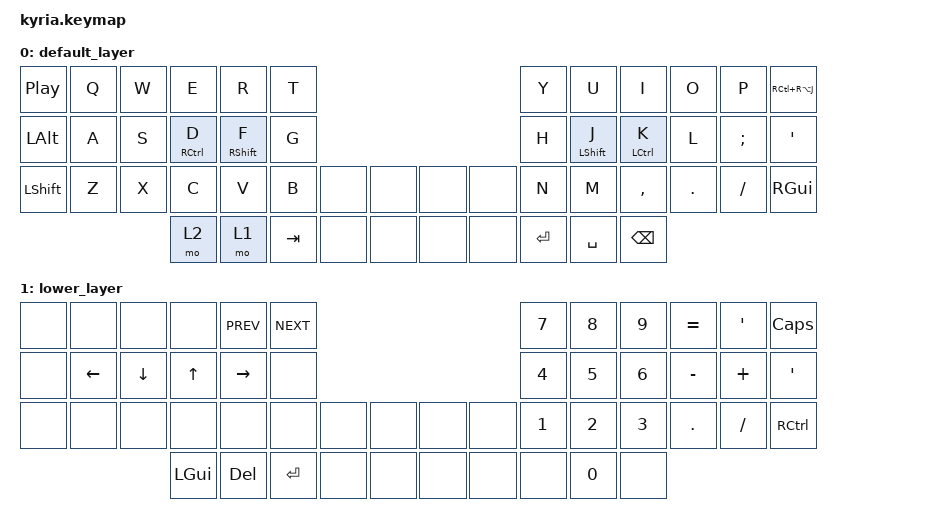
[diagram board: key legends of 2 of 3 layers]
/*
 * Copyright (c) 2020 The ZMK Contributors
 *
 * SPDX-License-Identifier: MIT
 */

#include <behaviors.dtsi>
#include <dt-bindings/zmk/keys.h>
#include <dt-bindings/zmk/bt.h>
&left_encoder { resolution = <3>; };
&kscan0 {
    debounce-period = <7>;
};

/ {
    combos {
        compatible = "zmk,combos";
        combo_esc {
            timeout-ms = <80>;
            key-positions = <5 17>;
            bindings = <&kp LALT>;
        };
    };
};

/ {
    behaviors {
        hm: homerow_mods {
            compatible = "zmk,behavior-hold-tap";
            label = "HOMEROW_MODS";
            #binding-cells = <2>;
            tapping-term-ms = <200>;
            quick_tap_ms = <0>;
            flavor = "balanced";
            bindings = <&kp>, <&kp>;
        };
    };
};


/ {
	keymap {
		compatible = "zmk,keymap";

		default_layer {
// ---------------------------------------------------------------------------------------------------------------------------------
// |  PP   |  Q  |  W  |  E   |  R   |  T   |                           |  Y   |  U    |  I    |  O   |   P   |   \  |
// |  ALT  |  A  |  S  |  D   |  F   |  G   |                           |  H   |  J    |  K    |  L   |   ;   |   '  |
// | SHIFT |  Z  |  X  |  C   |  V   |  B   |   |    |          |   |   |  N   |  M    |  ,    |  .   |   /   | GUI  |
//                     |  L2  |  L1  | TAB  |   |    |          |   |   | ENTER| SPACE |  BSPC |
			bindings = <
	&kp C_PP  &kp Q   &kp W   &kp E       &kp R       &kp T                                     &kp Y   &kp U       &kp I       &kp O   &kp P    &kp RC(RA(J))
	&kp LALT  &kp A   &kp S   &hm RCTRL D &hm RSHFT F &kp G                                     &kp H   &hm LSHFT J &hm LCTRL K &kp L   &kp SEMI &kp SQT
	&kp LSHFT &kp Z   &kp X   &kp C       &kp V       &kp B   &none &none        &none &none   &kp N   &kp M       &kp COMMA   &kp DOT &kp FSLH &kp RGUI
	                          &mo 2       &mo 1       &kp TAB &none &none        &none &none   &kp RET &kp SPACE   &kp BSPC
			>;
			sensor-bindings = <&inc_dec_kp C_VOL_UP C_VOL_DN>;
		};	
		lower_layer {
// ---------------------------------------------------------------------------------------------------------------------------------
// |       |     |     |      | PREV | NEXT |                                |  7   |  8    |  9    |  0   |   '   |   \  |
// |       | LEFT|DOWN | UP   |RIGHT |      |                                |  4   |  5    |  6    |  -   |   +   |   '  |
// |       |     |     |      |      |      |    |    |            |   |     |  1   |  2    |  3    |  .   |   /   | CTRL |
//                     | GUI  | DEL  | RET  |    |    |            |   |     |      |  0    |       |
			bindings = < 
&none  &none     &none    &none     &kp C_PREV &kp C_NEXT                               &kp N7 &kp N8  &kp N9  &kp EQUAL  &kp SQT  &kp CAPS
&none  &kp LEFT  &kp DOWN &kp UP    &kp RIGHT  &none                                    &kp N4 &kp N5  &kp N6  &kp MINUS  &kp PLUS &kp SQT
&none  &none     &none    &none     &none      &none   &none &none       &none &none    &kp N1 &kp N2  &kp N3  &kp DOT    &kp FSLH &kp RCTRL
	                  &kp LGUI  &kp DEL    &kp RET &none &none       &none &none    &none  &kp N0  &none		
			>;
			sensor-bindings = <&inc_dec_kp C_NEXT C_PREV>;
		};	
		
		raise_layer {
// ---------------------------------------------------------------------------------------------------------------------------------
// |  ESC  |  !  |  @  |  #   |  $   |  %   |                                          |  ^   |  &    |  *    |  (   |   )   |   \  |
// |  TAB  |  A  |  S  |  D   |  F   |  G   |                                          |  -   |  =    |  [    |  ]   |   |   |   '  |
// | SHIFT |  Z  |  X  |  C   |  V   |  B   | L SHIFT | L SHIFT |  | L SHIFT | L SHIFT |  \   |  ~    |       |      |        | CTRL |
//                     | GUI  | DEL  | RET  |  SPACE  |   ESC   |  |   RET   |  SPACE  | TAB  | BSPC  | R-ALT |
			bindings = <
   &kp  ESC  &kp EXCL   &kp AT       &kp HASH     &kp DLLR     &kp PRCNT       &kp CARET &kp AMPS  &kp KP_MULTIPLY &kp LPAR &kp RPAR &kp BSPC
   &kp LCTRL &trans     &trans       &trans       &kp PLUS     &kp MINUS       &kp MINUS &kp EQUAL &kp LBKT        &kp RBKT &kp PIPE &kp GRAVE
   &kp LSHFT &bt BT_CLR &bt BT_SEL 0 &bt BT_SEL 1 &bt BT_SEL 2 &bt BT_SEL 3    &kp UNDER &kp PLUS  &trans          &trans   &kp BSLH &kp TILDE
	                    &kp LGUI &kp DEL &kp RET &kp SPACE &kp ESC         &kp RET   &kp SPACE &kp TAB &kp BSPC &kp RALT		
			>;
			sensor-bindings = <&inc_dec_kp C_PREV C_NEXT>;
		};
	};
};
